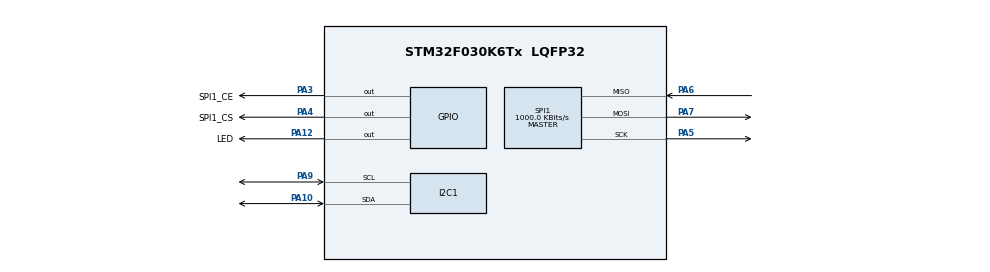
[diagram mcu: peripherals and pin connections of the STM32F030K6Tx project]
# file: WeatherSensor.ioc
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Mcu.Family=STM32F0
Mcu.Name=STM32F030K6Tx
Mcu.Package=LQFP32
NVIC.RTC_IRQn=true\:0\:0\:false\:false\:false\:true\:false
PA10.Mode=I2C
PA10.Signal=I2C1_SDA
PA12.GPIO_Label=LED
PA12.Signal=GPIO_Output
PA13.Mode=Serial_Wire
PA13.Signal=SYS_SWDIO
PA14.Mode=Serial_Wire
PA14.Signal=SYS_SWCLK
PA3.GPIO_Label=SPI1_CE
PA3.Signal=GPIO_Output
PA4.GPIO_Label=SPI1_CS
PA4.Signal=GPIO_Output
PA5.Mode=Full_Duplex_Master
PA5.Signal=SPI1_SCK
PA6.Mode=Full_Duplex_Master
PA6.Signal=SPI1_MISO
PA7.Mode=Full_Duplex_Master
PA7.Signal=SPI1_MOSI
PA9.Mode=I2C
PA9.Signal=I2C1_SCL
ProjectManager.HeapSize=0x200
ProjectManager.StackSize=0x400
ProjectManager.TargetToolchain=STM32CubeIDE
RCC.AHBCLKDivider=RCC_SYSCLK_DIV4
RCC.AHBFreq_Value=2000000
RCC.APB1Freq_Value=2000000
RCC.APB1TimFreq_Value=2000000
RCC.HCLKFreq_Value=2000000
RCC.PREFETCH_ENABLE=1
RTC.Alarm=RTC_ALARM_A
RTC.AlarmMaskDateWeekDay=RTC_ALARMMASK_DATEWEEKDAY
RTC.Format=RTC_FORMAT_BCD
RTC.Minutes_A=0
RTC.Seconds_A=30
SPI1.CalculateBaudRate=1000.0 KBits/s
SPI1.DataSize=SPI_DATASIZE_8BIT
SPI1.Direction=SPI_DIRECTION_2LINES
SPI1.Mode=SPI_MODE_MASTER
SPI1.VirtualType=VM_MASTER
TIM17.Period=65535
TIM17.Prescaler=1
VP_RTC_VS_RTC_Activate.Mode=RTC_Enabled
VP_RTC_VS_RTC_Alarm_A_Intern.Mode=Alarm A
VP_RTC_VS_RTC_Calendar.Mode=RTC_Calendar
VP_TIM17_VS_ClockSourceINT.Mode=Enable_Timer
board=custom

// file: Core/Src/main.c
/* USER CODE BEGIN Header */
/**
  ******************************************************************************
  * @file           : main.c
  * @brief          : Main program body
  ******************************************************************************
  * @attention
  *
  * <h2><center>&copy; Copyright (c) 2020 STMicroelectronics.
  * All rights reserved.</center></h2>
  *
  * This software component is licensed by ST under BSD 3-Clause license,
  * the "License"; You may not use this file except in compliance with the
  * License. You may obtain a copy of the License at:
  *                        opensource.org/licenses/BSD-3-Clause
  *
  ******************************************************************************
  */
/* USER CODE END Header */
#include "main.h"

/* USER CODE BEGIN Includes */
#include "core.h"

/* USER CODE END Includes */

I2C_HandleTypeDef hi2c1;

RTC_HandleTypeDef hrtc;

SPI_HandleTypeDef hspi1;

TIM_HandleTypeDef htim17;

void SystemClock_Config(void);
static void MX_GPIO_Init(void);
static void MX_I2C1_Init(void);
static void MX_SPI1_Init(void);
static void MX_RTC_Init(void);
static void MX_TIM17_Init(void);

int main(void)
{

  /* MCU Configuration--------------------------------------------------------*/

  /* Reset of all peripherals, Initializes the Flash interface and the Systick. */
  HAL_Init();

  /* Configure the system clock */
  SystemClock_Config();

  /* Initialize all configured peripherals */
  MX_GPIO_Init();
  MX_I2C1_Init();
  MX_SPI1_Init();
  MX_RTC_Init();
  MX_TIM17_Init();
  /* USER CODE BEGIN 2 */
  start();

  /* USER CODE END 2 */

  /* Infinite loop */
  while (1)
  {

    /* USER CODE BEGIN 3 */
	  update();
  }
  /* USER CODE END 3 */
}

void SystemClock_Config(void)
{
  RCC_OscInitTypeDef RCC_OscInitStruct = {0};
  RCC_ClkInitTypeDef RCC_ClkInitStruct = {0};
  RCC_PeriphCLKInitTypeDef PeriphClkInit = {0};

  /** Initializes the RCC Oscillators according to the specified parameters
  * in the RCC_OscInitTypeDef structure.
  */
  RCC_OscInitStruct.OscillatorType = RCC_OSCILLATORTYPE_HSI|RCC_OSCILLATORTYPE_LSI;
  RCC_OscInitStruct.HSIState = RCC_HSI_ON;
  RCC_OscInitStruct.HSICalibrationValue = RCC_HSICALIBRATION_DEFAULT;
  RCC_OscInitStruct.LSIState = RCC_LSI_ON;
  RCC_OscInitStruct.PLL.PLLState = RCC_PLL_NONE;
  if (HAL_RCC_OscConfig(&RCC_OscInitStruct) != HAL_OK)
  {
    Error_Handler();
  }
  /** Initializes the CPU, AHB and APB buses clocks
  */
  RCC_ClkInitStruct.ClockType = RCC_CLOCKTYPE_HCLK|RCC_CLOCKTYPE_SYSCLK
                              |RCC_CLOCKTYPE_PCLK1;
  RCC_ClkInitStruct.SYSCLKSource = RCC_SYSCLKSOURCE_HSI;
  RCC_ClkInitStruct.AHBCLKDivider = RCC_SYSCLK_DIV4;
  RCC_ClkInitStruct.APB1CLKDivider = RCC_HCLK_DIV1;

  if (HAL_RCC_ClockConfig(&RCC_ClkInitStruct, FLASH_LATENCY_0) != HAL_OK)
  {
    Error_Handler();
  }
  PeriphClkInit.PeriphClockSelection = RCC_PERIPHCLK_I2C1|RCC_PERIPHCLK_RTC;
  PeriphClkInit.I2c1ClockSelection = RCC_I2C1CLKSOURCE_HSI;
  PeriphClkInit.RTCClockSelection = RCC_RTCCLKSOURCE_LSI;
  if (HAL_RCCEx_PeriphCLKConfig(&PeriphClkInit) != HAL_OK)
  {
    Error_Handler();
  }
}

static void MX_I2C1_Init(void)
{

  hi2c1.Instance = I2C1;
  hi2c1.Init.Timing = 0x2000090E;
  hi2c1.Init.OwnAddress1 = 0;
  hi2c1.Init.AddressingMode = I2C_ADDRESSINGMODE_7BIT;
  hi2c1.Init.DualAddressMode = I2C_DUALADDRESS_DISABLE;
  hi2c1.Init.OwnAddress2 = 0;
  hi2c1.Init.OwnAddress2Masks = I2C_OA2_NOMASK;
  hi2c1.Init.GeneralCallMode = I2C_GENERALCALL_DISABLE;
  hi2c1.Init.NoStretchMode = I2C_NOSTRETCH_DISABLE;
  if (HAL_I2C_Init(&hi2c1) != HAL_OK)
  {
    Error_Handler();
  }
  /** Configure Analogue filter
  */
  if (HAL_I2CEx_ConfigAnalogFilter(&hi2c1, I2C_ANALOGFILTER_ENABLE) != HAL_OK)
  {
    Error_Handler();
  }
  /** Configure Digital filter
  */
  if (HAL_I2CEx_ConfigDigitalFilter(&hi2c1, 0) != HAL_OK)
  {
    Error_Handler();
  }

}

static void MX_RTC_Init(void)
{

  RTC_TimeTypeDef sTime = {0};
  RTC_DateTypeDef sDate = {0};
  RTC_AlarmTypeDef sAlarm = {0};

  /** Initialize RTC Only
  */
  hrtc.Instance = RTC;
  hrtc.Init.HourFormat = RTC_HOURFORMAT_24;
  hrtc.Init.AsynchPrediv = 127;
  hrtc.Init.SynchPrediv = 255;
  hrtc.Init.OutPut = RTC_OUTPUT_DISABLE;
  hrtc.Init.OutPutPolarity = RTC_OUTPUT_POLARITY_HIGH;
  hrtc.Init.OutPutType = RTC_OUTPUT_TYPE_OPENDRAIN;
  if (HAL_RTC_Init(&hrtc) != HAL_OK)
  {
    Error_Handler();
  }

  /** Initialize RTC and set the Time and Date
  */
  sTime.Hours = 0x0;
  sTime.Minutes = 0x0;
  sTime.Seconds = 0x0;
  sTime.DayLightSaving = RTC_DAYLIGHTSAVING_NONE;
  sTime.StoreOperation = RTC_STOREOPERATION_RESET;
  if (HAL_RTC_SetTime(&hrtc, &sTime, RTC_FORMAT_BCD) != HAL_OK)
  {
    Error_Handler();
  }
  sDate.WeekDay = RTC_WEEKDAY_MONDAY;
  sDate.Month = RTC_MONTH_JANUARY;
  sDate.Date = 0x1;
  sDate.Year = 0x0;

  if (HAL_RTC_SetDate(&hrtc, &sDate, RTC_FORMAT_BCD) != HAL_OK)
  {
    Error_Handler();
  }
  /** Enable the Alarm A
  */
  sAlarm.AlarmTime.Hours = 0x0;
  sAlarm.AlarmTime.Minutes = 0x0;
  sAlarm.AlarmTime.Seconds = 0x30;
  sAlarm.AlarmTime.SubSeconds = 0x0;
  sAlarm.AlarmTime.DayLightSaving = RTC_DAYLIGHTSAVING_NONE;
  sAlarm.AlarmTime.StoreOperation = RTC_STOREOPERATION_RESET;
  sAlarm.AlarmMask = RTC_ALARMMASK_DATEWEEKDAY;
  sAlarm.AlarmSubSecondMask = RTC_ALARMSUBSECONDMASK_ALL;
  sAlarm.AlarmDateWeekDaySel = RTC_ALARMDATEWEEKDAYSEL_DATE;
  sAlarm.AlarmDateWeekDay = 0x1;
  sAlarm.Alarm = RTC_ALARM_A;
  if (HAL_RTC_SetAlarm_IT(&hrtc, &sAlarm, RTC_FORMAT_BCD) != HAL_OK)
  {
    Error_Handler();
  }

}

static void MX_SPI1_Init(void)
{

  /* SPI1 parameter configuration*/
  hspi1.Instance = SPI1;
  hspi1.Init.Mode = SPI_MODE_MASTER;
  hspi1.Init.Direction = SPI_DIRECTION_2LINES;
  hspi1.Init.DataSize = SPI_DATASIZE_8BIT;
  hspi1.Init.CLKPolarity = SPI_POLARITY_LOW;
  hspi1.Init.CLKPhase = SPI_PHASE_1EDGE;
  hspi1.Init.NSS = SPI_NSS_SOFT;
  hspi1.Init.BaudRatePrescaler = SPI_BAUDRATEPRESCALER_2;
  hspi1.Init.FirstBit = SPI_FIRSTBIT_MSB;
  hspi1.Init.TIMode = SPI_TIMODE_DISABLE;
  hspi1.Init.CRCCalculation = SPI_CRCCALCULATION_DISABLE;
  hspi1.Init.CRCPolynomial = 7;
  hspi1.Init.CRCLength = SPI_CRC_LENGTH_DATASIZE;
  hspi1.Init.NSSPMode = SPI_NSS_PULSE_ENABLE;
  if (HAL_SPI_Init(&hspi1) != HAL_OK)
  {
    Error_Handler();
  }

}

static void MX_TIM17_Init(void)
{

  htim17.Instance = TIM17;
  htim17.Init.Prescaler = 1;
  htim17.Init.CounterMode = TIM_COUNTERMODE_UP;
  htim17.Init.Period = 65535;
  htim17.Init.ClockDivision = TIM_CLOCKDIVISION_DIV1;
  htim17.Init.RepetitionCounter = 0;
  htim17.Init.AutoReloadPreload = TIM_AUTORELOAD_PRELOAD_DISABLE;
  if (HAL_TIM_Base_Init(&htim17) != HAL_OK)
  {
    Error_Handler();
  }

}

static void MX_GPIO_Init(void)
{
  GPIO_InitTypeDef GPIO_InitStruct = {0};

  /* GPIO Ports Clock Enable */
  __HAL_RCC_GPIOF_CLK_ENABLE();
  __HAL_RCC_GPIOA_CLK_ENABLE();
  __HAL_RCC_GPIOB_CLK_ENABLE();

  /*Configure GPIO pin Output Level */
  HAL_GPIO_WritePin(GPIOA, SPI1_CE_Pin|SPI1_CS_Pin|LED_Pin, GPIO_PIN_RESET);

  /*Configure GPIO pins : PF0 PF1 */
  GPIO_InitStruct.Pin = GPIO_PIN_0|GPIO_PIN_1;
  GPIO_InitStruct.Mode = GPIO_MODE_ANALOG;
  GPIO_InitStruct.Pull = GPIO_NOPULL;
  HAL_GPIO_Init(GPIOF, &GPIO_InitStruct);

  /*Configure GPIO pins : PA0 PA1 PA2 PA8
                           PA11 PA15 */
  GPIO_InitStruct.Pin = GPIO_PIN_0|GPIO_PIN_1|GPIO_PIN_2|GPIO_PIN_8
                          |GPIO_PIN_11|GPIO_PIN_15;
  GPIO_InitStruct.Mode = GPIO_MODE_ANALOG;
  GPIO_InitStruct.Pull = GPIO_NOPULL;
  HAL_GPIO_Init(GPIOA, &GPIO_InitStruct);

  /*Configure GPIO pins : SPI1_CE_Pin SPI1_CS_Pin LED_Pin */
  GPIO_InitStruct.Pin = SPI1_CE_Pin|SPI1_CS_Pin|LED_Pin;
  GPIO_InitStruct.Mode = GPIO_MODE_OUTPUT_PP;
  GPIO_InitStruct.Pull = GPIO_NOPULL;
  GPIO_InitStruct.Speed = GPIO_SPEED_FREQ_LOW;
  HAL_GPIO_Init(GPIOA, &GPIO_InitStruct);

  /*Configure GPIO pins : PB0 PB1 PB3 PB4
                           PB5 PB6 PB7 */
  GPIO_InitStruct.Pin = GPIO_PIN_0|GPIO_PIN_1|GPIO_PIN_3|GPIO_PIN_4
                          |GPIO_PIN_5|GPIO_PIN_6|GPIO_PIN_7;
  GPIO_InitStruct.Mode = GPIO_MODE_ANALOG;
  GPIO_InitStruct.Pull = GPIO_NOPULL;
  HAL_GPIO_Init(GPIOB, &GPIO_InitStruct);

}

void Error_Handler(void)
{
}

/************************ (C) COPYRIGHT STMicroelectronics *****END OF FILE****/
